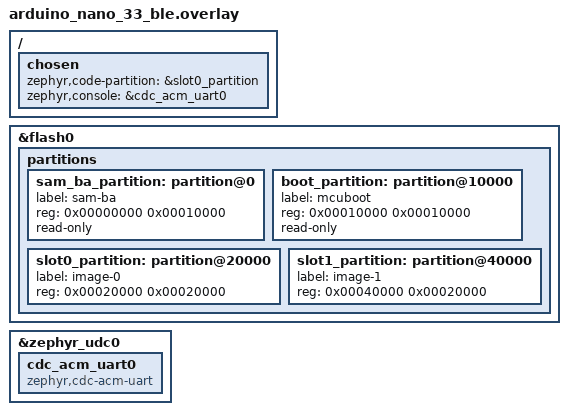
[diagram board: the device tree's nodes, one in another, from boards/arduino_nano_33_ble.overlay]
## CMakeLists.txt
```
cmake_minimum_required(VERSION 3.20.0)
find_package(Zephyr REQUIRED HINTS $ENV{ZEPHYR_BASE})
project(mcuboot_lab_hello)
target_sources(app PRIVATE src/main.c)
```

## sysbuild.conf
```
SB_CONFIG_BOOTLOADER_MCUBOOT=y
SB_CONFIG_BOOT_SIGNATURE_TYPE_ECDSA_P256=y
SB_CONFIG_BOOT_SIGNATURE_KEY_FILE="/home/astro/zephyrproject/mcuboot-lab/keys/lab-signing-key.pem"
SB_CONFIG_MCUBOOT_MODE_OVERWRITE_ONLY=y
```

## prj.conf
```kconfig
CONFIG_GPIO=y
CONFIG_SERIAL=y
CONFIG_CONSOLE=y
CONFIG_UART_CONSOLE=y
CONFIG_STDOUT_CONSOLE=y
CONFIG_UART_LINE_CTRL=y
CONFIG_PRINTK=y
CONFIG_USB_DEVICE_STACK_NEXT=y
CONFIG_CDC_ACM_SERIAL_INITIALIZE_AT_BOOT=y
CONFIG_CDC_ACM_SERIAL_PRODUCT_STRING="MCUboot lab"
```

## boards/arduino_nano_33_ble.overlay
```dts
/delete-node/ &boot_partition;
/delete-node/ &code_partition;

&flash0 {
	partitions {
		sam_ba_partition: partition@0 {
			label = "sam-ba";
			reg = <0x00000000 0x00010000>;
			read-only;
		};

		boot_partition: partition@10000 {
			label = "mcuboot";
			reg = <0x00010000 0x00010000>;
			read-only;
		};

		slot0_partition: partition@20000 {
			label = "image-0";
			reg = <0x00020000 0x00020000>;
		};

		slot1_partition: partition@40000 {
			label = "image-1";
			reg = <0x00040000 0x00020000>;
		};
	};
};

/ {
	chosen {
		zephyr,code-partition = &slot0_partition;
	};
};

/ {
	chosen {
		zephyr,console = &cdc_acm_uart0;
	};
};

&zephyr_udc0 {
	cdc_acm_uart0: cdc_acm_uart0 {
		compatible = "zephyr,cdc-acm-uart";
	};
};
```

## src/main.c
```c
#include <zephyr/kernel.h>

int main(void)
{
	unsigned int n = 0;

	while (1) {
		printk("mcuboot-lab: app v1.0.0 running from slot 0, tick %u\n", n++);
		k_sleep(K_SECONDS(1));
	}
	return 0;
}
```
